# PY32T020xx register map
Vendor: Puya; Series: PY32L0; File version: 1.0.0
CPU: CM0+ r0p1, little endian, no MPU, no FPU, 4 interrupt priority bits
Registers are 32-bit, read-write, reset 0x0 unless marked. A register's access mark holds for its fields unless they carry their own. Offsets are from the block's base; [hi:lo] are bit positions.

## RCC — Reset and clock control
Base 0x40021000
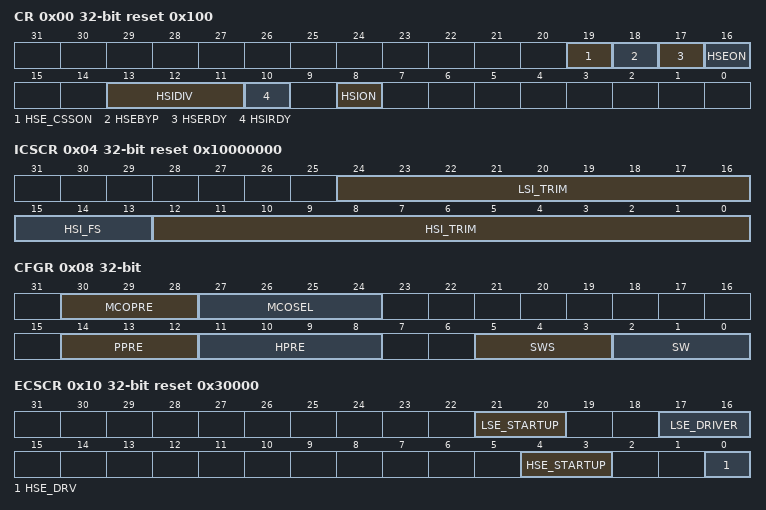
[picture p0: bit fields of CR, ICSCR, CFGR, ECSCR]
0x00 CR reset 0x100 — Clock control register
  [19] HSE_CSSON
  [18] HSEBYP — HSE crystal oscillator bypass
  [17] HSERDY — HSE clock ready flag
  [16] HSEON — HSE clock enable
  [13:11] HSIDIV — HSI16 clock division factor
  [10] HSIRDY — HSI16 clock ready flag
  [8] HSION — HSI16 clock enable
0x04 ICSCR reset 0x10000000 — Internal clock sources calibration register
  [24:16] LSI_TRIM — LSI clock trimming
  [15:13] HSI_FS — HSI frequency selection
  [12:0] HSI_TRIM — HSI clock trimming
0x08 CFGR — Clock configuration register
  [30:28] MCOPRE — Microcontroller clock output prescaler
  [27:24] MCOSEL — Microcontroller clock output
  [14:12] PPRE — APB prescaler
  [11:8] HPRE — AHB prescaler
  [5:3] SWS ro — System clock switch status
  [2:0] SW — System clock switch
0x10 ECSCR reset 0x30000 — External clock source control register
  [21:20] LSE_STARTUP, [17:16] LSE_DRIVER, [4:3] HSE_STARTUP, [0] HSE_DRV
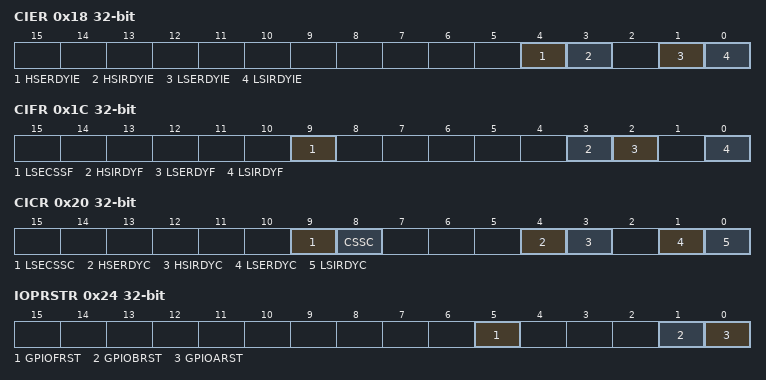
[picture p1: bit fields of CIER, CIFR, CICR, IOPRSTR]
0x18 CIER — Clock interrupt enable register
  [4] HSERDYIE — HSE ready interrupt enable
  [3] HSIRDYIE — HSI ready interrupt enable
  [1] LSERDYIE — LSE ready interrupt enable
  [0] LSIRDYIE — LSI ready interrupt enable
0x1C CIFR ro — Clock interrupt flag register
  [9] LSECSSF — LSE clock secure system interrupt flag
  [3] HSIRDYF — HSI ready interrupt flag
  [2] LSERDYF — LSE ready interrupt flag
  [0] LSIRDYF — LSI ready interrupt flag
0x20 CICR wo — Clock interrupt clear register
  [9] LSECSSC — LSE clock secure system interrupt flag clear
  [8] CSSC — clock secure system interrupt flag clear
  [4] HSERDYC — HSE ready interrupt clear
  [3] HSIRDYC — HSI ready interrupt clear
  [1] LSERDYC — LSE ready interrupt clear
  [0] LSIRDYC — LSI ready interrupt clear
0x24 IOPRSTR — GPIO reset register
  [5] GPIOFRST — I/O port F reset
  [1] GPIOBRST — I/O port B reset
  [0] GPIOARST — I/O port A reset
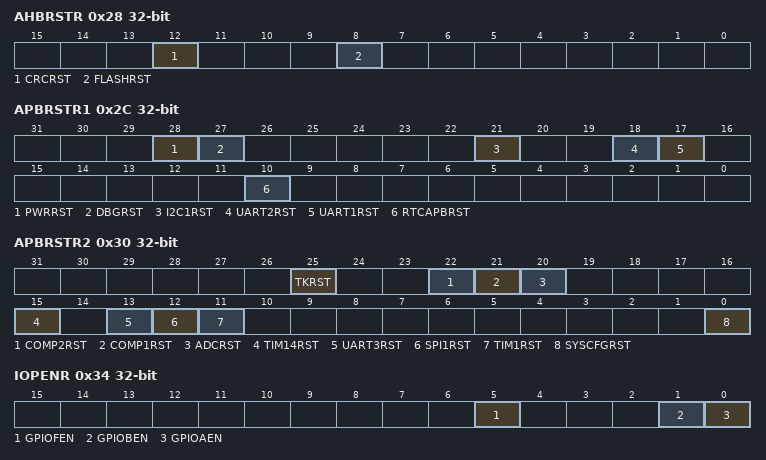
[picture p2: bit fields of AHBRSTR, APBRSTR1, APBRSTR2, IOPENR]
0x28 AHBRSTR — AHB peripheral reset register
  [12] CRCRST — CRC reset
  [8] FLASHRST — FLASH reset
0x2C APBRSTR1 — APB peripheral reset register 1
  [28] PWRRST — Power interface reset
  [27] DBGRST — Debug support reset
  [21] I2C1RST — I2C1 reset
  [18] UART2RST — UART2 reset
  [17] UART1RST — UART1 reset
  [10] RTCAPBRST
0x30 APBRSTR2 — APB peripheral reset register 2
  [25] TKRST — TK reset
  [22] COMP2RST — COMP2 reset
  [21] COMP1RST — COMP1 reset
  [20] ADCRST — ADC reset
  [15] TIM14RST — TIM14 reset
  [13] UART3RST — UART3 reset
  [12] SPI1RST — SPI1 reset
  [11] TIM1RST — TIM1 timer reset
  [0] SYSCFGRST — SYSCFG reset
0x34 IOPENR — GPIO clock enable register
  [5] GPIOFEN — I/O port F clock enable
  [1] GPIOBEN — I/O port B clock enable
  [0] GPIOAEN — I/O port A clock enable
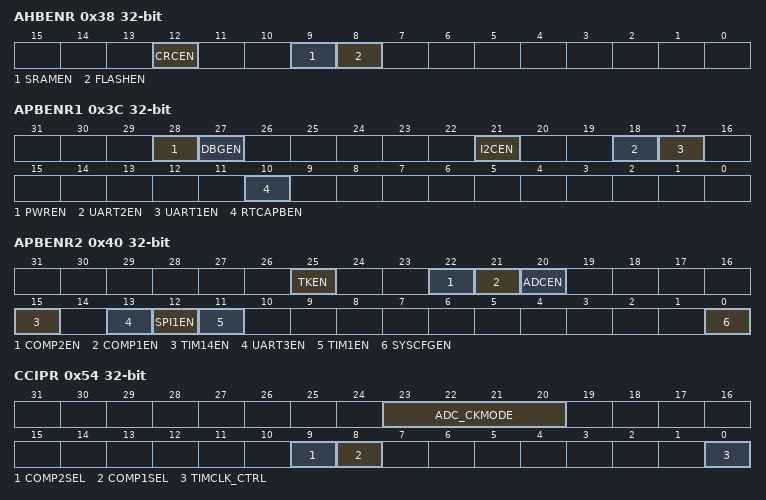
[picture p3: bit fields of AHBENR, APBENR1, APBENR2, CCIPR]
0x38 AHBENR — AHB peripheral clock enable register
  [12] CRCEN — CRC clock enable
  [9] SRAMEN — SRAM memory interface clock enable
  [8] FLASHEN — Flash memory interface clock enable
0x3C APBENR1 — APB peripheral clock enable register 1
  [28] PWREN — Power interface clock enable
  [27] DBGEN — Debug support clock enable
  [21] I2CEN — I2C clock enable
  [18] UART2EN — UART2 clock enable
  [17] UART1EN — UART1 clock enable
  [10] RTCAPBEN
0x40 APBENR2 — APB peripheral clock enable register 2
  [25] TKEN — TK clock enable
  [22] COMP2EN — COMP2 clock enable
  [21] COMP1EN — COMP1 clock enable
  [20] ADCEN — ADC clock enable
  [15] TIM14EN — TIM14 clock enable
  [13] UART3EN — UART3 clock enable
  [12] SPI1EN — SPI1 clock enable
  [11] TIM1EN — TIM1 timer clock enable
  [0] SYSCFGEN — SYSCFG, COMP and VREFBUF clock enable
0x54 CCIPR — Peripherals independent clock configuration register
  [23:20] ADC_CKMODE, [9] COMP2SEL, [8] COMP1SEL, [0] TIMCLK_CTRL
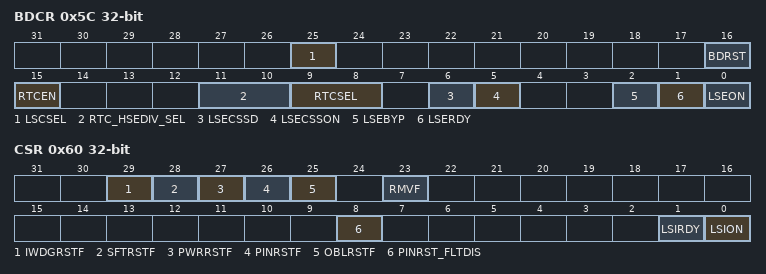
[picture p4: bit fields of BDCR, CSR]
0x5C BDCR — RTC domain control register
  [25] LSCSEL
  [16] BDRST — RTC domain software reset
  [15] RTCEN — RTC clock source enable
  [11:10] RTC_HSEDIV_SEL
  [9:8] RTCSEL — RTC clock source selection
  [6] LSECSSD — LSE CSS detect
  [5] LSECSSON — LSE CSS enable
  [2] LSEBYP — LSE oscillator bypass
  [1] LSERDY — LSE oscillator ready
  [0] LSEON — LSE oscillator enable
0x60 CSR ro — Control/status register
  [29] IWDGRSTF — Independent window watchdog reset flag
  [28] SFTRSTF — Software reset flag
  [27] PWRRSTF — BOR or POR/PDR flag
  [26] PINRSTF — Pin reset flag
  [25] OBLRSTF — Option byte loader reset flag
  [23] RMVF — Remove reset flags
  [8] PINRST_FLTDIS
  [1] LSIRDY — LSI oscillator ready
  [0] LSION — LSI oscillator enable
